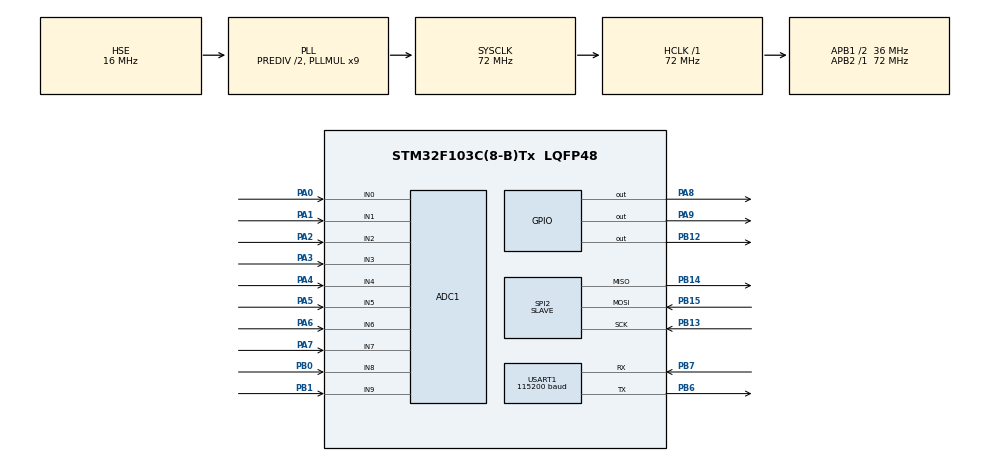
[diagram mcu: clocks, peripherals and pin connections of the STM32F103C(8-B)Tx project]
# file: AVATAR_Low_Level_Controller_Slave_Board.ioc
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ADC1.Channel-0\#ChannelRegularConversion=ADC_CHANNEL_0
ADC1.Channel-1\#ChannelRegularConversion=ADC_CHANNEL_1
ADC1.Channel-12\#ChannelRegularConversion=ADC_CHANNEL_8
ADC1.Channel-14\#ChannelRegularConversion=ADC_CHANNEL_9
ADC1.Channel-2\#ChannelRegularConversion=ADC_CHANNEL_2
ADC1.Channel-3\#ChannelRegularConversion=ADC_CHANNEL_3
ADC1.Channel-4\#ChannelRegularConversion=ADC_CHANNEL_4
ADC1.Channel-5\#ChannelRegularConversion=ADC_CHANNEL_5
ADC1.Channel-6\#ChannelRegularConversion=ADC_CHANNEL_6
ADC1.Channel-7\#ChannelRegularConversion=ADC_CHANNEL_7
ADC1.ContinuousConvMode=DISABLE
ADC1.DiscontinuousConvMode=DISABLE
ADC1.NbrOfConversion=10
ADC1.NbrOfConversionFlag=1
ADC1.Rank-0\#ChannelRegularConversion=1
ADC1.Rank-1\#ChannelRegularConversion=2
ADC1.Rank-12\#ChannelRegularConversion=9
ADC1.Rank-14\#ChannelRegularConversion=10
ADC1.Rank-2\#ChannelRegularConversion=3
ADC1.Rank-3\#ChannelRegularConversion=4
ADC1.Rank-4\#ChannelRegularConversion=5
ADC1.Rank-5\#ChannelRegularConversion=6
ADC1.Rank-6\#ChannelRegularConversion=7
ADC1.Rank-7\#ChannelRegularConversion=8
ADC1.SamplingTime-0\#ChannelRegularConversion=ADC_SAMPLETIME_239CYCLES_5
ADC1.SamplingTime-1\#ChannelRegularConversion=ADC_SAMPLETIME_239CYCLES_5
ADC1.SamplingTime-12\#ChannelRegularConversion=ADC_SAMPLETIME_239CYCLES_5
ADC1.SamplingTime-14\#ChannelRegularConversion=ADC_SAMPLETIME_239CYCLES_5
ADC1.SamplingTime-2\#ChannelRegularConversion=ADC_SAMPLETIME_239CYCLES_5
ADC1.SamplingTime-3\#ChannelRegularConversion=ADC_SAMPLETIME_239CYCLES_5
ADC1.SamplingTime-4\#ChannelRegularConversion=ADC_SAMPLETIME_239CYCLES_5
ADC1.SamplingTime-5\#ChannelRegularConversion=ADC_SAMPLETIME_239CYCLES_5
ADC1.SamplingTime-6\#ChannelRegularConversion=ADC_SAMPLETIME_239CYCLES_5
ADC1.SamplingTime-7\#ChannelRegularConversion=ADC_SAMPLETIME_239CYCLES_5
ADC1.master=1
Dma.ADC1.0.Direction=DMA_PERIPH_TO_MEMORY
Dma.ADC1.0.Instance=DMA1_Channel1
Dma.ADC1.0.MemDataAlignment=DMA_MDATAALIGN_WORD
Dma.ADC1.0.MemInc=DMA_MINC_ENABLE
Dma.ADC1.0.Mode=DMA_NORMAL
Dma.ADC1.0.PeriphDataAlignment=DMA_PDATAALIGN_WORD
Dma.ADC1.0.PeriphInc=DMA_PINC_DISABLE
Dma.ADC1.0.Priority=DMA_PRIORITY_LOW
Dma.Request0=ADC1
Dma.Request1=SPI2_RX
Dma.Request2=SPI2_TX
Dma.SPI2_RX.1.Direction=DMA_PERIPH_TO_MEMORY
Dma.SPI2_RX.1.Instance=DMA1_Channel4
Dma.SPI2_RX.1.MemDataAlignment=DMA_MDATAALIGN_BYTE
Dma.SPI2_RX.1.MemInc=DMA_MINC_ENABLE
Dma.SPI2_RX.1.Mode=DMA_NORMAL
Dma.SPI2_RX.1.PeriphDataAlignment=DMA_PDATAALIGN_BYTE
Dma.SPI2_RX.1.PeriphInc=DMA_PINC_DISABLE
Dma.SPI2_RX.1.Priority=DMA_PRIORITY_LOW
Dma.SPI2_TX.2.Direction=DMA_MEMORY_TO_PERIPH
Dma.SPI2_TX.2.Instance=DMA1_Channel5
Dma.SPI2_TX.2.MemDataAlignment=DMA_MDATAALIGN_BYTE
Dma.SPI2_TX.2.MemInc=DMA_MINC_ENABLE
Dma.SPI2_TX.2.Mode=DMA_NORMAL
Dma.SPI2_TX.2.PeriphDataAlignment=DMA_PDATAALIGN_BYTE
Dma.SPI2_TX.2.PeriphInc=DMA_PINC_DISABLE
Dma.SPI2_TX.2.Priority=DMA_PRIORITY_LOW
FREERTOS.Tasks01=spiTask,0,128,SPITaskFunction,Default,NULL,Dynamic,NULL,NULL;uartTask,2,128,UARTTaskFunction,Default,NULL,Dynamic,NULL,NULL
FREERTOS.configUSE_NEWLIB_REENTRANT=1
Mcu.Family=STM32F1
Mcu.Name=STM32F103C(8-B)Tx
Mcu.Package=LQFP48
NVIC.DMA1_Channel1_IRQn=true\:5\:0\:true\:false\:true\:true\:false\:true\:true
NVIC.DMA1_Channel4_IRQn=true\:5\:0\:false\:false\:true\:true\:false\:true\:true
NVIC.DMA1_Channel5_IRQn=true\:5\:0\:true\:false\:true\:true\:false\:true\:true
NVIC.PriorityGroup=NVIC_PRIORITYGROUP_4
NVIC.TIM1_BRK_IRQn=true\:5\:0\:false\:false\:true\:true\:true\:true\:true
NVIC.TIM1_CC_IRQn=true\:5\:0\:false\:false\:true\:true\:true\:true\:true
NVIC.TIM1_TRG_COM_IRQn=true\:5\:0\:false\:false\:true\:true\:true\:true\:true
NVIC.TIM1_UP_IRQn=true\:5\:0\:false\:false\:true\:true\:true\:true\:true
NVIC.TIM4_IRQn=true\:15\:0\:false\:false\:true\:false\:false\:true\:true
NVIC.TimeBase=TIM4_IRQn
NVIC.TimeBaseIP=TIM4
NVIC.USART1_IRQn=true\:5\:0\:true\:false\:true\:false\:true\:true\:true
PA0-WKUP.Signal=ADCx_IN0
PA1.Signal=ADCx_IN1
PA13.Mode=Serial_Wire
PA13.Signal=SYS_JTMS-SWDIO
PA14.Mode=Serial_Wire
PA14.Signal=SYS_JTCK-SWCLK
PA2.Signal=ADCx_IN2
PA3.Signal=ADCx_IN3
PA4.Signal=ADCx_IN4
PA5.Signal=ADCx_IN5
PA6.Signal=ADCx_IN6
PA7.Signal=ADCx_IN7
PA8.Signal=GPIO_Output
PA9.Signal=GPIO_Output
PB0.Signal=ADCx_IN8
PB1.Signal=ADCx_IN9
PB12.Signal=GPIO_Output
PB13.Mode=Full_Duplex_Slave
PB13.Signal=SPI2_SCK
PB14.Mode=Full_Duplex_Slave
PB14.Signal=SPI2_MISO
PB15.Mode=Full_Duplex_Slave
PB15.Signal=SPI2_MOSI
PB6.Mode=Asynchronous
PB6.Signal=USART1_TX
PB7.Mode=Asynchronous
PB7.Signal=USART1_RX
PD0-OSC_IN.Mode=HSE-External-Oscillator
PD0-OSC_IN.Signal=RCC_OSC_IN
PD1-OSC_OUT.Mode=HSE-External-Oscillator
PD1-OSC_OUT.Signal=RCC_OSC_OUT
ProjectManager.HeapSize=0x200
ProjectManager.StackSize=0x400
ProjectManager.TargetToolchain=STM32CubeIDE
RCC.ADCPresc=RCC_ADCPCLK2_DIV6
RCC.AHBFreq_Value=72000000
RCC.APB1CLKDivider=RCC_HCLK_DIV2
RCC.APB1Freq_Value=36000000
RCC.APB1TimFreq_Value=72000000
RCC.APB2Freq_Value=72000000
RCC.APB2TimFreq_Value=72000000
RCC.HCLKFreq_Value=72000000
RCC.HSEDivPLL=RCC_HSE_PREDIV_DIV2
RCC.HSE_VALUE=16000000
RCC.PLLMUL=RCC_PLL_MUL9
RCC.PLLSourceVirtual=RCC_PLLSOURCE_HSE
RCC.SYSCLKFreq_VALUE=72000000
RCC.SYSCLKSource=RCC_SYSCLKSOURCE_PLLCLK
RCC.USBFreq_Value=72000000
SH.ADCx_IN0.0=ADC1_IN0,IN0
SH.ADCx_IN1.0=ADC1_IN1,IN1
SH.ADCx_IN2.0=ADC1_IN2,IN2
SH.ADCx_IN3.0=ADC1_IN3,IN3
SH.ADCx_IN4.0=ADC1_IN4,IN4
SH.ADCx_IN5.0=ADC1_IN5,IN5
SH.ADCx_IN6.0=ADC1_IN6,IN6
SH.ADCx_IN7.0=ADC1_IN7,IN7
SH.ADCx_IN8.0=ADC1_IN8,IN8
SH.ADCx_IN9.0=ADC1_IN9,IN9
SPI2.CLKPhase=SPI_PHASE_2EDGE
SPI2.CLKPolarity=SPI_POLARITY_LOW
SPI2.Direction=SPI_DIRECTION_2LINES
SPI2.Mode=SPI_MODE_SLAVE
SPI2.VirtualType=VM_SLAVE
TIM1.Period=10-1
TIM1.Prescaler=7200-1
USART1.BaudRate=115200
USART1.VirtualMode=VM_ASYNC
VP_FREERTOS_VS_CMSIS_V1.Mode=CMSIS_V1
VP_SYS_VS_tim4.Mode=TIM4
VP_TIM1_VS_ClockSourceINT.Mode=Internal
board=custom

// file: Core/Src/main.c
/* USER CODE BEGIN Header */
/**
  ******************************************************************************
  * @file           : main.c
  * @brief          : Main program body
  ******************************************************************************
  * @attention
  *
  * Copyright (c) 2024 STMicroelectronics.
  * All rights reserved.
  *
  * This software is licensed under terms that can be found in the LICENSE file
  * in the root directory of this software component.
  * If no LICENSE file comes with this software, it is provided AS-IS.
  *
  ******************************************************************************
  */
/* USER CODE END Header */
#include "main.h"
#include "cmsis_os.h"

/* USER CODE BEGIN Includes */
#include "low_level_controller_slave_main.h"
#include "low_level_controller_slave_callbacks.h"
/* USER CODE END Includes */

ADC_HandleTypeDef hadc1;
DMA_HandleTypeDef hdma_adc1;

SPI_HandleTypeDef hspi2;
DMA_HandleTypeDef hdma_spi2_rx;
DMA_HandleTypeDef hdma_spi2_tx;

TIM_HandleTypeDef htim1;

UART_HandleTypeDef huart1;

osThreadId spiTaskHandle;
osThreadId uartTaskHandle;

void SystemClock_Config(void);
static void MX_GPIO_Init(void);
static void MX_DMA_Init(void);
static void MX_SPI2_Init(void);
static void MX_USART1_UART_Init(void);
static void MX_ADC1_Init(void);
static void MX_TIM1_Init(void);
void SPITaskFunction(void const * argument);
void UARTTaskFunction(void const * argument);

int main(void)
{

  /* MCU Configuration--------------------------------------------------------*/

  /* Reset of all peripherals, Initializes the Flash interface and the Systick. */
  HAL_Init();

  /* Configure the system clock */
  SystemClock_Config();

  /* Initialize all configured peripherals */
  MX_GPIO_Init();
  MX_DMA_Init();
  MX_SPI2_Init();
  MX_USART1_UART_Init();
  MX_ADC1_Init();
  MX_TIM1_Init();
  /* USER CODE BEGIN 2 */

  Start();

  /* USER CODE END 2 */

  /* Create the thread(s) */
  /* definition and creation of spiTask */
  osThreadDef(spiTask, SPITaskFunction, osPriorityNormal, 0, 128);
  spiTaskHandle = osThreadCreate(osThread(spiTask), NULL);

  /* definition and creation of uartTask */
  osThreadDef(uartTask, UARTTaskFunction, osPriorityHigh, 0, 128);
  uartTaskHandle = osThreadCreate(osThread(uartTask), NULL);

  /* Start scheduler */
  osKernelStart();

  /* We should never get here as control is now taken by the scheduler */

  /* Infinite loop */
  while (1)
  {

  }
}

void SystemClock_Config(void)
{
  RCC_OscInitTypeDef RCC_OscInitStruct = {0};
  RCC_ClkInitTypeDef RCC_ClkInitStruct = {0};
  RCC_PeriphCLKInitTypeDef PeriphClkInit = {0};

  /** Initializes the RCC Oscillators according to the specified parameters
  * in the RCC_OscInitTypeDef structure.
  */
  RCC_OscInitStruct.OscillatorType = RCC_OSCILLATORTYPE_HSE;
  RCC_OscInitStruct.HSEState = RCC_HSE_ON;
  RCC_OscInitStruct.HSEPredivValue = RCC_HSE_PREDIV_DIV2;
  RCC_OscInitStruct.HSIState = RCC_HSI_ON;
  RCC_OscInitStruct.PLL.PLLState = RCC_PLL_ON;
  RCC_OscInitStruct.PLL.PLLSource = RCC_PLLSOURCE_HSE;
  RCC_OscInitStruct.PLL.PLLMUL = RCC_PLL_MUL9;
  if (HAL_RCC_OscConfig(&RCC_OscInitStruct) != HAL_OK)
  {
    Error_Handler();
  }

  /** Initializes the CPU, AHB and APB buses clocks
  */
  RCC_ClkInitStruct.ClockType = RCC_CLOCKTYPE_HCLK|RCC_CLOCKTYPE_SYSCLK
                              |RCC_CLOCKTYPE_PCLK1|RCC_CLOCKTYPE_PCLK2;
  RCC_ClkInitStruct.SYSCLKSource = RCC_SYSCLKSOURCE_PLLCLK;
  RCC_ClkInitStruct.AHBCLKDivider = RCC_SYSCLK_DIV1;
  RCC_ClkInitStruct.APB1CLKDivider = RCC_HCLK_DIV2;
  RCC_ClkInitStruct.APB2CLKDivider = RCC_HCLK_DIV1;

  if (HAL_RCC_ClockConfig(&RCC_ClkInitStruct, FLASH_LATENCY_2) != HAL_OK)
  {
    Error_Handler();
  }
  PeriphClkInit.PeriphClockSelection = RCC_PERIPHCLK_ADC;
  PeriphClkInit.AdcClockSelection = RCC_ADCPCLK2_DIV6;
  if (HAL_RCCEx_PeriphCLKConfig(&PeriphClkInit) != HAL_OK)
  {
    Error_Handler();
  }
}

static void MX_ADC1_Init(void)
{

  ADC_ChannelConfTypeDef sConfig = {0};

  /** Common config
  */
  hadc1.Instance = ADC1;
  hadc1.Init.ScanConvMode = ADC_SCAN_ENABLE;
  hadc1.Init.ContinuousConvMode = DISABLE;
  hadc1.Init.DiscontinuousConvMode = DISABLE;
  hadc1.Init.ExternalTrigConv = ADC_SOFTWARE_START;
  hadc1.Init.DataAlign = ADC_DATAALIGN_RIGHT;
  hadc1.Init.NbrOfConversion = 10;
  if (HAL_ADC_Init(&hadc1) != HAL_OK)
  {
    Error_Handler();
  }

  /** Configure Regular Channel
  */
  sConfig.Channel = ADC_CHANNEL_0;
  sConfig.Rank = ADC_REGULAR_RANK_1;
  sConfig.SamplingTime = ADC_SAMPLETIME_239CYCLES_5;
  if (HAL_ADC_ConfigChannel(&hadc1, &sConfig) != HAL_OK)
  {
    Error_Handler();
  }

  /** Configure Regular Channel
  */
  sConfig.Channel = ADC_CHANNEL_1;
  sConfig.Rank = ADC_REGULAR_RANK_2;
  if (HAL_ADC_ConfigChannel(&hadc1, &sConfig) != HAL_OK)
  {
    Error_Handler();
  }

  /** Configure Regular Channel
  */
  sConfig.Channel = ADC_CHANNEL_2;
  sConfig.Rank = ADC_REGULAR_RANK_3;
  if (HAL_ADC_ConfigChannel(&hadc1, &sConfig) != HAL_OK)
  {
    Error_Handler();
  }

  /** Configure Regular Channel
  */
  sConfig.Channel = ADC_CHANNEL_3;
  sConfig.Rank = ADC_REGULAR_RANK_4;
  if (HAL_ADC_ConfigChannel(&hadc1, &sConfig) != HAL_OK)
  {
    Error_Handler();
  }

  /** Configure Regular Channel
  */
  sConfig.Channel = ADC_CHANNEL_4;
  sConfig.Rank = ADC_REGULAR_RANK_5;
  if (HAL_ADC_ConfigChannel(&hadc1, &sConfig) != HAL_OK)
  {
    Error_Handler();
  }

  /** Configure Regular Channel
  */
  sConfig.Channel = ADC_CHANNEL_5;
  sConfig.Rank = ADC_REGULAR_RANK_6;
  if (HAL_ADC_ConfigChannel(&hadc1, &sConfig) != HAL_OK)
  {
    Error_Handler();
  }

  /** Configure Regular Channel
  */
  sConfig.Channel = ADC_CHANNEL_6;
  sConfig.Rank = ADC_REGULAR_RANK_7;
  if (HAL_ADC_ConfigChannel(&hadc1, &sConfig) != HAL_OK)
  {
    Error_Handler();
  }

  /** Configure Regular Channel
  */
  sConfig.Channel = ADC_CHANNEL_7;
  sConfig.Rank = ADC_REGULAR_RANK_8;
  if (HAL_ADC_ConfigChannel(&hadc1, &sConfig) != HAL_OK)
  {
    Error_Handler();
  }

  /** Configure Regular Channel
  */
  sConfig.Channel = ADC_CHANNEL_8;
  sConfig.Rank = ADC_REGULAR_RANK_9;
  if (HAL_ADC_ConfigChannel(&hadc1, &sConfig) != HAL_OK)
  {
    Error_Handler();
  }

  /** Configure Regular Channel
  */
  sConfig.Channel = ADC_CHANNEL_9;
  sConfig.Rank = ADC_REGULAR_RANK_10;
  if (HAL_ADC_ConfigChannel(&hadc1, &sConfig) != HAL_OK)
  {
    Error_Handler();
  }

}

static void MX_SPI2_Init(void)
{

  /* SPI2 parameter configuration*/
  hspi2.Instance = SPI2;
  hspi2.Init.Mode = SPI_MODE_SLAVE;
  hspi2.Init.Direction = SPI_DIRECTION_2LINES;
  hspi2.Init.DataSize = SPI_DATASIZE_8BIT;
  hspi2.Init.CLKPolarity = SPI_POLARITY_LOW;
  hspi2.Init.CLKPhase = SPI_PHASE_2EDGE;
  hspi2.Init.NSS = SPI_NSS_SOFT;
  hspi2.Init.FirstBit = SPI_FIRSTBIT_MSB;
  hspi2.Init.TIMode = SPI_TIMODE_DISABLE;
  hspi2.Init.CRCCalculation = SPI_CRCCALCULATION_DISABLE;
  hspi2.Init.CRCPolynomial = 10;
  if (HAL_SPI_Init(&hspi2) != HAL_OK)
  {
    Error_Handler();
  }

}

static void MX_TIM1_Init(void)
{

  TIM_ClockConfigTypeDef sClockSourceConfig = {0};
  TIM_MasterConfigTypeDef sMasterConfig = {0};

  htim1.Instance = TIM1;
  htim1.Init.Prescaler = 7200-1;
  htim1.Init.CounterMode = TIM_COUNTERMODE_UP;
  htim1.Init.Period = 10-1;
  htim1.Init.ClockDivision = TIM_CLOCKDIVISION_DIV1;
  htim1.Init.RepetitionCounter = 0;
  htim1.Init.AutoReloadPreload = TIM_AUTORELOAD_PRELOAD_DISABLE;
  if (HAL_TIM_Base_Init(&htim1) != HAL_OK)
  {
    Error_Handler();
  }
  sClockSourceConfig.ClockSource = TIM_CLOCKSOURCE_INTERNAL;
  if (HAL_TIM_ConfigClockSource(&htim1, &sClockSourceConfig) != HAL_OK)
  {
    Error_Handler();
  }
  sMasterConfig.MasterOutputTrigger = TIM_TRGO_RESET;
  sMasterConfig.MasterSlaveMode = TIM_MASTERSLAVEMODE_DISABLE;
  if (HAL_TIMEx_MasterConfigSynchronization(&htim1, &sMasterConfig) != HAL_OK)
  {
    Error_Handler();
  }

}

static void MX_USART1_UART_Init(void)
{

  huart1.Instance = USART1;
  huart1.Init.BaudRate = 115200;
  huart1.Init.WordLength = UART_WORDLENGTH_8B;
  huart1.Init.StopBits = UART_STOPBITS_1;
  huart1.Init.Parity = UART_PARITY_NONE;
  huart1.Init.Mode = UART_MODE_TX_RX;
  huart1.Init.HwFlowCtl = UART_HWCONTROL_NONE;
  huart1.Init.OverSampling = UART_OVERSAMPLING_16;
  if (HAL_UART_Init(&huart1) != HAL_OK)
  {
    Error_Handler();
  }

}

static void MX_DMA_Init(void)
{

  /* DMA controller clock enable */
  __HAL_RCC_DMA1_CLK_ENABLE();

  /* DMA interrupt init */
  /* DMA1_Channel1_IRQn interrupt configuration */
  HAL_NVIC_SetPriority(DMA1_Channel1_IRQn, 5, 0);
  HAL_NVIC_EnableIRQ(DMA1_Channel1_IRQn);
  /* DMA1_Channel4_IRQn interrupt configuration */
  HAL_NVIC_SetPriority(DMA1_Channel4_IRQn, 5, 0);
  HAL_NVIC_EnableIRQ(DMA1_Channel4_IRQn);
  /* DMA1_Channel5_IRQn interrupt configuration */
  HAL_NVIC_SetPriority(DMA1_Channel5_IRQn, 5, 0);
  HAL_NVIC_EnableIRQ(DMA1_Channel5_IRQn);

}

static void MX_GPIO_Init(void)
{
  GPIO_InitTypeDef GPIO_InitStruct = {0};

  /* GPIO Ports Clock Enable */
  __HAL_RCC_GPIOD_CLK_ENABLE();
  __HAL_RCC_GPIOA_CLK_ENABLE();
  __HAL_RCC_GPIOB_CLK_ENABLE();

  /*Configure GPIO pin Output Level */
  HAL_GPIO_WritePin(GPIOB, GPIO_PIN_12, GPIO_PIN_RESET);

  /*Configure GPIO pin Output Level */
  HAL_GPIO_WritePin(GPIOA, GPIO_PIN_8|GPIO_PIN_9, GPIO_PIN_RESET);

  /*Configure GPIO pin : PB12 */
  GPIO_InitStruct.Pin = GPIO_PIN_12;
  GPIO_InitStruct.Mode = GPIO_MODE_OUTPUT_PP;
  GPIO_InitStruct.Pull = GPIO_NOPULL;
  GPIO_InitStruct.Speed = GPIO_SPEED_FREQ_LOW;
  HAL_GPIO_Init(GPIOB, &GPIO_InitStruct);

  /*Configure GPIO pins : PA8 PA9 */
  GPIO_InitStruct.Pin = GPIO_PIN_8|GPIO_PIN_9;
  GPIO_InitStruct.Mode = GPIO_MODE_OUTPUT_PP;
  GPIO_InitStruct.Pull = GPIO_NOPULL;
  GPIO_InitStruct.Speed = GPIO_SPEED_FREQ_LOW;
  HAL_GPIO_Init(GPIOA, &GPIO_InitStruct);

}

void SPITaskFunction(void const * argument)
{
  /* USER CODE BEGIN 5 */
  /* Infinite loop */
  for(;;)
  {
	  SPI_Callback();
	  osDelay(1);
  }
  /* USER CODE END 5 */
}

void UARTTaskFunction(void const * argument)
{
  /* USER CODE BEGIN UARTTaskFunction */
  /* Infinite loop */
  for(;;)
  {
	  UART_Callback();
//	  osDelay(1);
  }
  /* USER CODE END UARTTaskFunction */
}

void HAL_TIM_PeriodElapsedCallback(TIM_HandleTypeDef *htim)
{
  if (htim->Instance == TIM4) {
    HAL_IncTick();
  }
  /* USER CODE BEGIN Callback 1 */
  	  On_Timer_Tick(htim);
  /* USER CODE END Callback 1 */
}

void Error_Handler(void)
{
  __disable_irq();
  while (1)
  {
  }
}
